# R7FA6T2BD register map
Vendor: Renesas Electronics Corporation; Series: RA6; File version: 1.40.00
CPU: CM33 r0p4, little endian, MPU, FPU, VTOR, 4 interrupt priority bits, 96 interrupts
Registers are 32-bit, read-write, reset 0x0 unless marked. A register's access mark holds for its fields unless they carry their own. Offsets are from the block's base; [hi:lo] are bit positions.

## SCI_B0 — Serial Communication Interface 0
Base 0x40118000
Same registers: SCI_B1 0x40118100, SCI_B2 0x40118200, SCI_B3 0x40118300, SCI_B4 0x40118400, SCI_B9 0x40118900
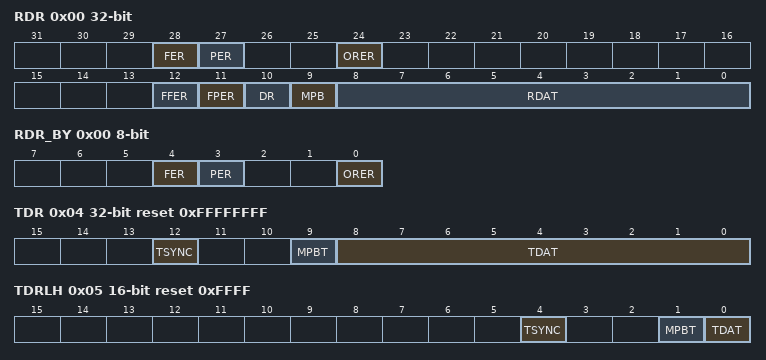
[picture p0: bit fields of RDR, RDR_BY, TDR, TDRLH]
0x00 RDR ro — Receive Data Register
  [28] FER — Framing error flag
  [27] PER — Parity error flag
  [24] ORER — Overrun Error flag
  [12] FFER — FIFO framing error flag
  [11] FPER — FIFO parity error flag
  [10] DR — Receive data ready flag
  [9] MPB — Multi,processor flag
  [8:0] RDAT — Serial receive data
0x00 RDR_BY 8-bit ro (alternate view of RDR) — Receive Data Register
  [4] FER — Framing error flag
  [3] PER — Parity error flag
  [0] ORER — Overrun Error flag
0x04 TDR reset 0xFFFFFFFF — Transmit Data Register
  [12] TSYNC — Transmit SYNC data
  [9] MPBT — Multi,processor transfer bit flag
  [8:0] TDAT — Serial transmit data
0x04 TDRLL 16-bit reset 0xFFFF (alternate view of TDR) — Transmit Data Register
0x05 TDRLH 16-bit reset 0xFFFF (alternate view of TDR) — Transmit Data Register
  [4] TSYNC — Transmit SYNC data
  [1] MPBT — Multi,processor transfer bit flag
  [0] TDAT — Serial transmit data
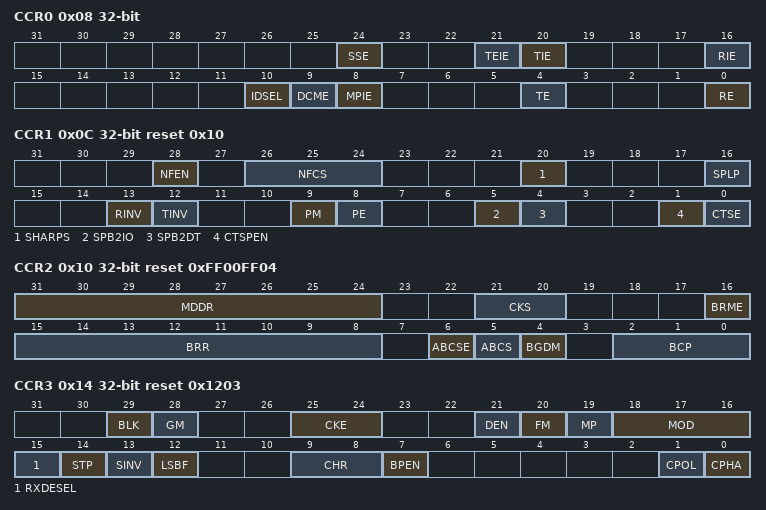
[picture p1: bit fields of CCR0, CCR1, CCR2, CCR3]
0x08 CCR0 — Common Control Register 0
  [24] SSE — SSn Pin Function Enable
  [21] TEIE — Transmit End Interrupt Enable
  [20] TIE — Transmit Interrupt Enable
  [16] RIE — Receive Interrupt Enable
  [10] IDSEL — ID frame select
  [9] DCME — Data Compare Match Enable
  [8] MPIE — Multi,Processor Interrupt Enable
  [4] TE — Transmit Enable
  [0] RE — Receive Enable
0x0C CCR1 reset 0x10 — Common Control Register 1
  [28] NFEN — Digital Noise Filter Function Enable
  [26:24] NFCS — Noise Filter Clock Select
  [20] SHARPS — Half,duplex communication select
  [16] SPLP — Loopback Control
  [13] RINV — RXD invert
  [12] TINV — TXD invert
  [9] PM — Parity Mode
  [8] PE — Parity Enable
  [5] SPB2IO — Serial port break I/O
  [4] SPB2DT — Serial port break data select
  [1] CTSPEN — CTS external pin Enable
  [0] CTSE — CTS Enable
0x10 CCR2 reset 0xFF00FF04 — Common Control Register 2
  [31:24] MDDR — Modulation Duty Setting
  [21:20] CKS — Clock Select
  [16] BRME — Bit Modulation Enable
  [15:8] BRR — Bit rate setting
  [6] ABCSE — Asynchronous Mode Extended Base Clock Select
  [5] ABCS — Asynchronous Mode Base Clock Select
  [4] BGDM — Baud Rate Generator Double,Speed Mode Select
  [2:0] BCP — Base Clock Pulse
0x14 CCR3 reset 0x1203 — Common Control Register 3
  [29] BLK — Block Transfer Mode
  [28] GM — GSM Mode
  [25:24] CKE — Clock enable
  [21] DEN — Driver enable
  [20] FM — FIFO Mode select
  [19] MP — Multi,Processor Mode
  [18:16] MOD — Communication mode select
  [15] RXDESEL — Asynchronous Start Bit Edge Detection Select
  [14] STP — Stop Bit Length
  [13] SINV — Transmitted/Received Data Invert
  [12] LSBF — LSB First select
  [9:8] CHR — Character Length
  [7] BPEN — Synchronizer bypass enable
  [1] CPOL — Clock Polarity Select
  [0] CPHA — Clock Phase Select
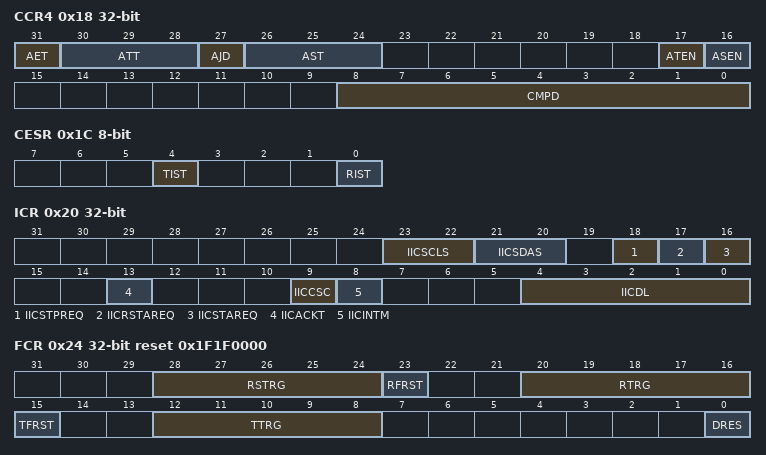
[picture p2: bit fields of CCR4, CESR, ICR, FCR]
0x18 CCR4 — Common Control Register 4
  [31] AET — Adjustment edge for transmit timing
  [30:28] ATT — Adjustment value for Transmit timing
  [27] AJD — Adjustment Direction for receive sampling timing
  [26:24] AST — Adjustment value for receive Sampling Timing
  [17] ATEN — Adjust transmit timing enable
  [16] ASEN — Adjust receive sampling timing enable
  [8:0] CMPD — Compare Match Data
0x1C CESR 8-bit ro — Communication Enable Status Register
  [4] TIST — TE Internal status
  [0] RIST — RE Internal status
0x20 ICR — Simple IIC Control Register
  [23:22] IICSCLS — SCL Output Select
  [21:20] IICSDAS — SDA Output Select
  [18] IICSTPREQ — Stop Condition Generation
  [17] IICRSTAREQ — Restart Condition Generation
  [16] IICSTAREQ — Start Condition Generation
  [13] IICACKT — ACK Transmission Data
  [9] IICCSC — Clock Synchronization
  [8] IICINTM — IIC Interrupt Mode Select
  [4:0] IICDL — SDA Delay Output Select
0x24 FCR reset 0x1F1F0000 — FIFO Control Register
  [28:24] RSTRG — RTS Output Active Trigger Number Select
  [23] RFRST wo — Receive FIFO Data Register Reset
  [20:16] RTRG — Receive FIFO data trigger number
  [15] TFRST wo — Transmit FIFO Data Register Reset
  [12:8] TTRG — Transmit FIFO data trigger number
  [0] DRES — Receive data ready error select bit
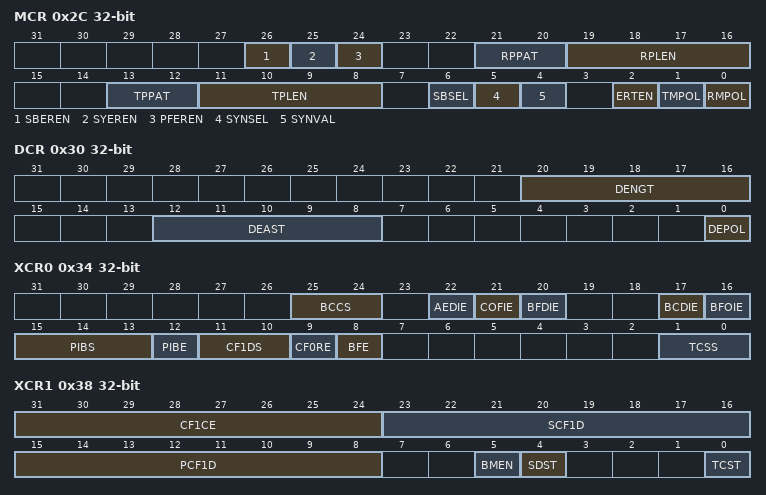
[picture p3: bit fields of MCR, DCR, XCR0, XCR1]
0x2C MCR — Manchester Control Register
  [26] SBEREN — Start Bit Error Enable
  [25] SYEREN — Receive SYNC Error Enable
  [24] PFEREN — Preface Error Enable
  [21:20] RPPAT — Receive Preface Pattern
  [19:16] RPLEN — Receive Preface Length
  [13:12] TPPAT — Transmit preface pattern
  [11:8] TPLEN — Transmit preface length
  [6] SBSEL — Start Bit Select
  [5] SYNSEL — SYNC Select
  [4] SYNVAL — SYNC value Setting
  [2] ERTEN — Manchester Edge Retiming Enable
  [1] TMPOL — Polarity of Transmit Manchester Code
  [0] RMPOL — Polarity of Received Manchester Code
0x30 DCR — Driver Control Register
  [20:16] DENGT — Driver negate time
  [12:8] DEAST — Driver Assertion Time
  [0] DEPOL — Driver effective polarity select
0x34 XCR0 — Simple LIN Control Register 0
  [25:24] BCCS — Bus conflict detection clock selection
  [22] AEDIE — Active edge detection interrupt enable
  [21] COFIE — Counter overflow interrupt enable
  [20] BFDIE — Break Field detection interrupt enable
  [17] BCDIE — Bus conflict detection interrupt enable
  [16] BFOIE — Break Field output completion interrupt enable
  [15:13] PIBS — Priority interrupt bit select
  [12] PIBE — Priority interrupt bit enable
  [11:10] CF1DS — Control Field1 compare data select
  [9] CF0RE — Control Field 0 enable
  [8] BFE — Break Field enable
  [1:0] TCSS — Timer count clock source selection
0x38 XCR1 — Simple LIN Control Register 1
  [31:24] CF1CE — Control Field 1 compare bit enable
  [23:16] SCF1D — Secondary compare data for Control Field 1
  [15:8] PCF1D — Priority compare data for Control Field 1
  [5] BMEN — Bit rate measurement enable
  [4] SDST — Start Frame detection enable
  [0] TCST — Break Field output timer count start trigger
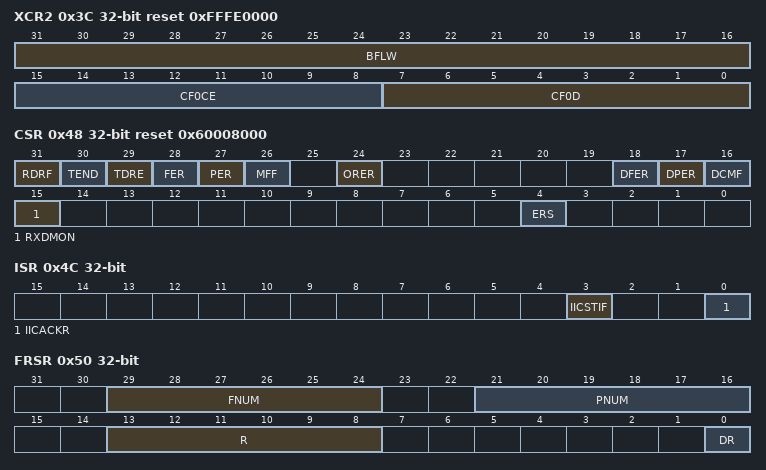
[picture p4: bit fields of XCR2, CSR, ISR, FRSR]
0x3C XCR2 reset 0xFFFE0000 — Simple LIN Control Register 2
  [31:16] BFLW — Break Field length setting
  [15:8] CF0CE — Control Field 0 compare bit enable
  [7:0] CF0D — Control Field 0 compare data
0x48 CSR ro reset 0x60008000 — Common Status Register
  [31] RDRF — Receive Data Full Flag
  [30] TEND — Transmit End Flag
  [29] TDRE — Transmit Data Empty Flag
  [28] FER — Framing Error Flag
  [27] PER — Parity Error Flag
  [26] MFF — Mode Fault Flag
  [24] ORER — Overrun Error Flag
  [18] DFER — Data Compare Match Framing Error Flag
  [17] DPER — Data Compare Match Parity Error Flag
  [16] DCMF — Data Compare Match Flag
  [15] RXDMON — Serial input data monitor bit
  [4] ERS — Error Signal Status Flag
0x4C ISR ro — Simple IIC Status Register
  [3] IICSTIF — Issuing of Start, Restart, or Stop Condition Completed Flag
  [0] IICACKR — ACK Reception Data Flag
0x50 FRSR ro — FIFO Receive Status Register
  [29:24] FNUM — Framing Error Count
  [21:16] PNUM — Parity Error Count
  [13:8] R — Receive,FIFO Data Count
  [0] DR — Receive Data Ready flag
0x54 FTSR ro — FIFO Transmit Status Register
  [5:0] T — Transmit,FIFO Data Count
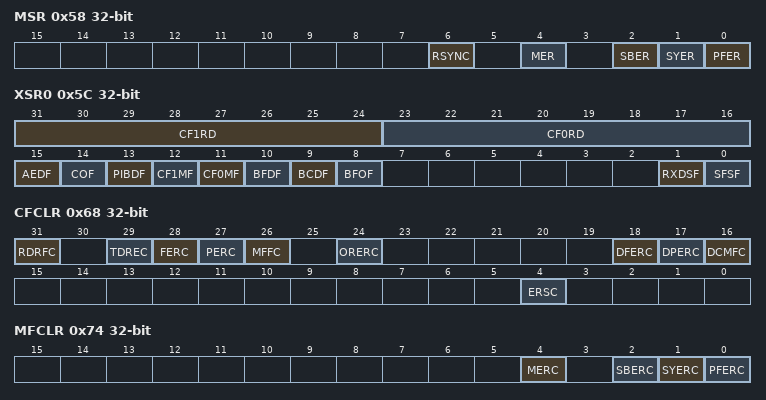
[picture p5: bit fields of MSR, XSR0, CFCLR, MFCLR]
0x58 MSR ro — Manchester Status Register
  [6] RSYNC — Receive SYNC data bit
  [4] MER — Manchester Error Flag
  [2] SBER — Start Bit Error flag
  [1] SYER — SYNC Error flag
  [0] PFER — Preface Error flag
0x5C XSR0 ro — Simple LIN Status Register 0
  [31:24] CF1RD — Control Field 1 received data
  [23:16] CF0RD — Control Field 0 received data
  [15] AEDF — Active Edge detection flag
  [14] COF — Counter Overflow flag
  [13] PIBDF — Priority interrupt bit detection flag
  [12] CF1MF — Control Field 1 compare match flag
  [11] CF0MF — Control Field 0 compare match flag
  [10] BFDF — Break Field detection flag
  [9] BCDF — Bus Conflict detection flag
  [8] BFOF — Break Field Output completion flag
  [1] RXDSF — RXDn input status flag
  [0] SFSF — Start Frame Status flag
0x60 XSR1 ro — Simple LIN Status Register 1
  [15:0] TCNT — Timer Count Capture value
0x68 CFCLR wo — Common Flag Clear Register
  [31] RDRFC — RDRF clear bit
  [29] TDREC — TDRE clear bit
  [28] FERC — FER clear bit
  [27] PERC — PER clear bit
  [26] MFFC — MFF clear bit
  [24] ORERC — ORER clear bit
  [18] DFERC — DFER clear bit
  [17] DPERC — DPER clear bit
  [16] DCMFC — DCMF clear bit
  [4] ERSC — ERS clear bit
0x6C ICFCLR wo — Simple IIC Flag Clear Register
  [3] IICSTIFC — IICSTIF clear bit
0x70 FFCLR wo — FIFO Flag Clear Register
  [0] DRC — DR clear bit
0x74 MFCLR wo — Manchester Flag Clear Register
  [4] MERC — MER clear bit
  [2] SBERC — SBER clear bit
  [1] SYERC — SYER clear bit
  [0] PFERC — PFER clear bit
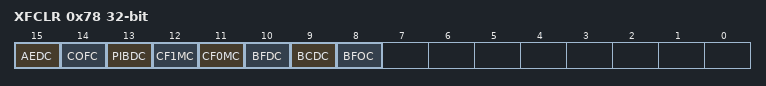
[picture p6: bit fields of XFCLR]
0x78 XFCLR wo — Simple LIN Flag Clear Register
  [15] AEDC — AEDF clear bit
  [14] COFC — COFF clear bit
  [13] PIBDC — PIBDF clear bit
  [12] CF1MC — CF1MF clear bit
  [11] CF0MC — CF0MF clear bit
  [10] BFDC — BFDF clear bit
  [9] BCDC — BCDF clear bit
  [8] BFOC — BFOF clear bit
